AUTOSAR XML (schema 314)
package /ComponentType
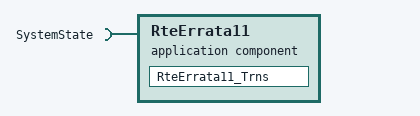
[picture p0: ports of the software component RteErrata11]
  application software component type RteErrata11  # This SWC contains definitions required to workaround Rte Generation errata following: 1) ESCAN00059438AN00059438 (corrected in Rte 2.22.00)
    require port SystemState: required-interface=SystemState
  internal behavior RteErrata11_InternalBehavior: component=RteErrata11, port-api-option{enable-take-address=false, indirect-api=false, port=SystemState}
    4 x mode switch event, all with start-on-event=RteErrata11_Trns, activation=ENTRY:
      MST_RteErrata11_Trns_0: mode=SystemState.Mode.OFF
      MST_RteErrata11_Trns_1: mode=SystemState.Mode.DISABLE
      MST_RteErrata11_Trns_2: mode=SystemState.Mode.WARMINIT
      MST_RteErrata11_Trns_3: mode=SystemState.Mode.OPERATE
    runnable RteErrata11_Trns
  swc implementation RteErrata11_Implementation: behavior=RteErrata11_InternalBehavior
    code-descriptors:
      code Code: type=SRC
